VERSION ""

NS_ :

BS_:

BU_:

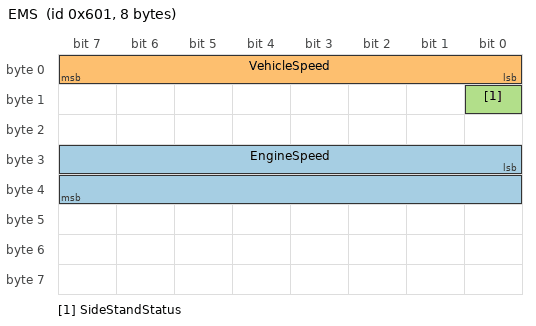
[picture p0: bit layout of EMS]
BO_ 1537 EMS: 8 Vector__XXX
	SG_ EngineSpeed : 24|16@1+ (0.125,0) [0|8031.875] "rpm" Vector__XXX
	SG_ VehicleSpeed : 0|8@1+ (0.1,0) [0|255] "kmph" Vector__XXX
	SG_ SideStandStatus : 8|1@1+ (1,0) [0|1] "" Vector__XXX

BO_ 1280 Cluster: 8 Vector__XXX
	SG_ FuelLevel : 0|4@1+ (1,0) [0|15] "ltr" Vector__XXX

CM_ BO_ 1537 "Electronic Engine Controller 1";
CM_ SG_ 1537 EngineSpeed "Actual engine speed in RPM";
CM_ BO_ 1280 "Instrument Cluster";
CM_ SG_ 1280 Fuel Level "Fuel level in litres";
BA_DEF_ SG_  "SPN" INT 0 524287;
BA_DEF_ BO_  "VFrameFormat" ENUM  "StandardCAN","ExtendedCAN","reserved","J1939PG";
BA_DEF_  "DatabaseVersion" STRING ;
BA_DEF_  "BusType" STRING ;
BA_DEF_  "ProtocolType" STRING ;
BA_DEF_  "DatabaseCompiler" STRING ;
BA_DEF_DEF_  "SPN" 0;
BA_DEF_DEF_  "VFrameFormat" "J1939PG";
BA_DEF_DEF_  "DatabaseVersion" "DEMO PLUS";
BA_DEF_DEF_  "BusType" "";
BA_DEF_DEF_  "ProtocolType" "";
BA_DEF_DEF_  "DatabaseCompiler" "";
BA_ "ProtocolType" "J1939";
BA_ "BusType" "CAN";
BA_ "DatabaseCompiler" "CSS ELECTRONICS (WWW.CSSELECTRONICS.COM)";
BA_ "DatabaseVersion" "1.0.0";
BA_ "SPN" SG_ 2364540158 EngineSpeed 190;
BA_ "SPN" SG_ 2566844926 WheelBasedVehicleSpeed 84;

VAL_ 1537 SideStandStatus 1 "DOWN" 0 "UP";
